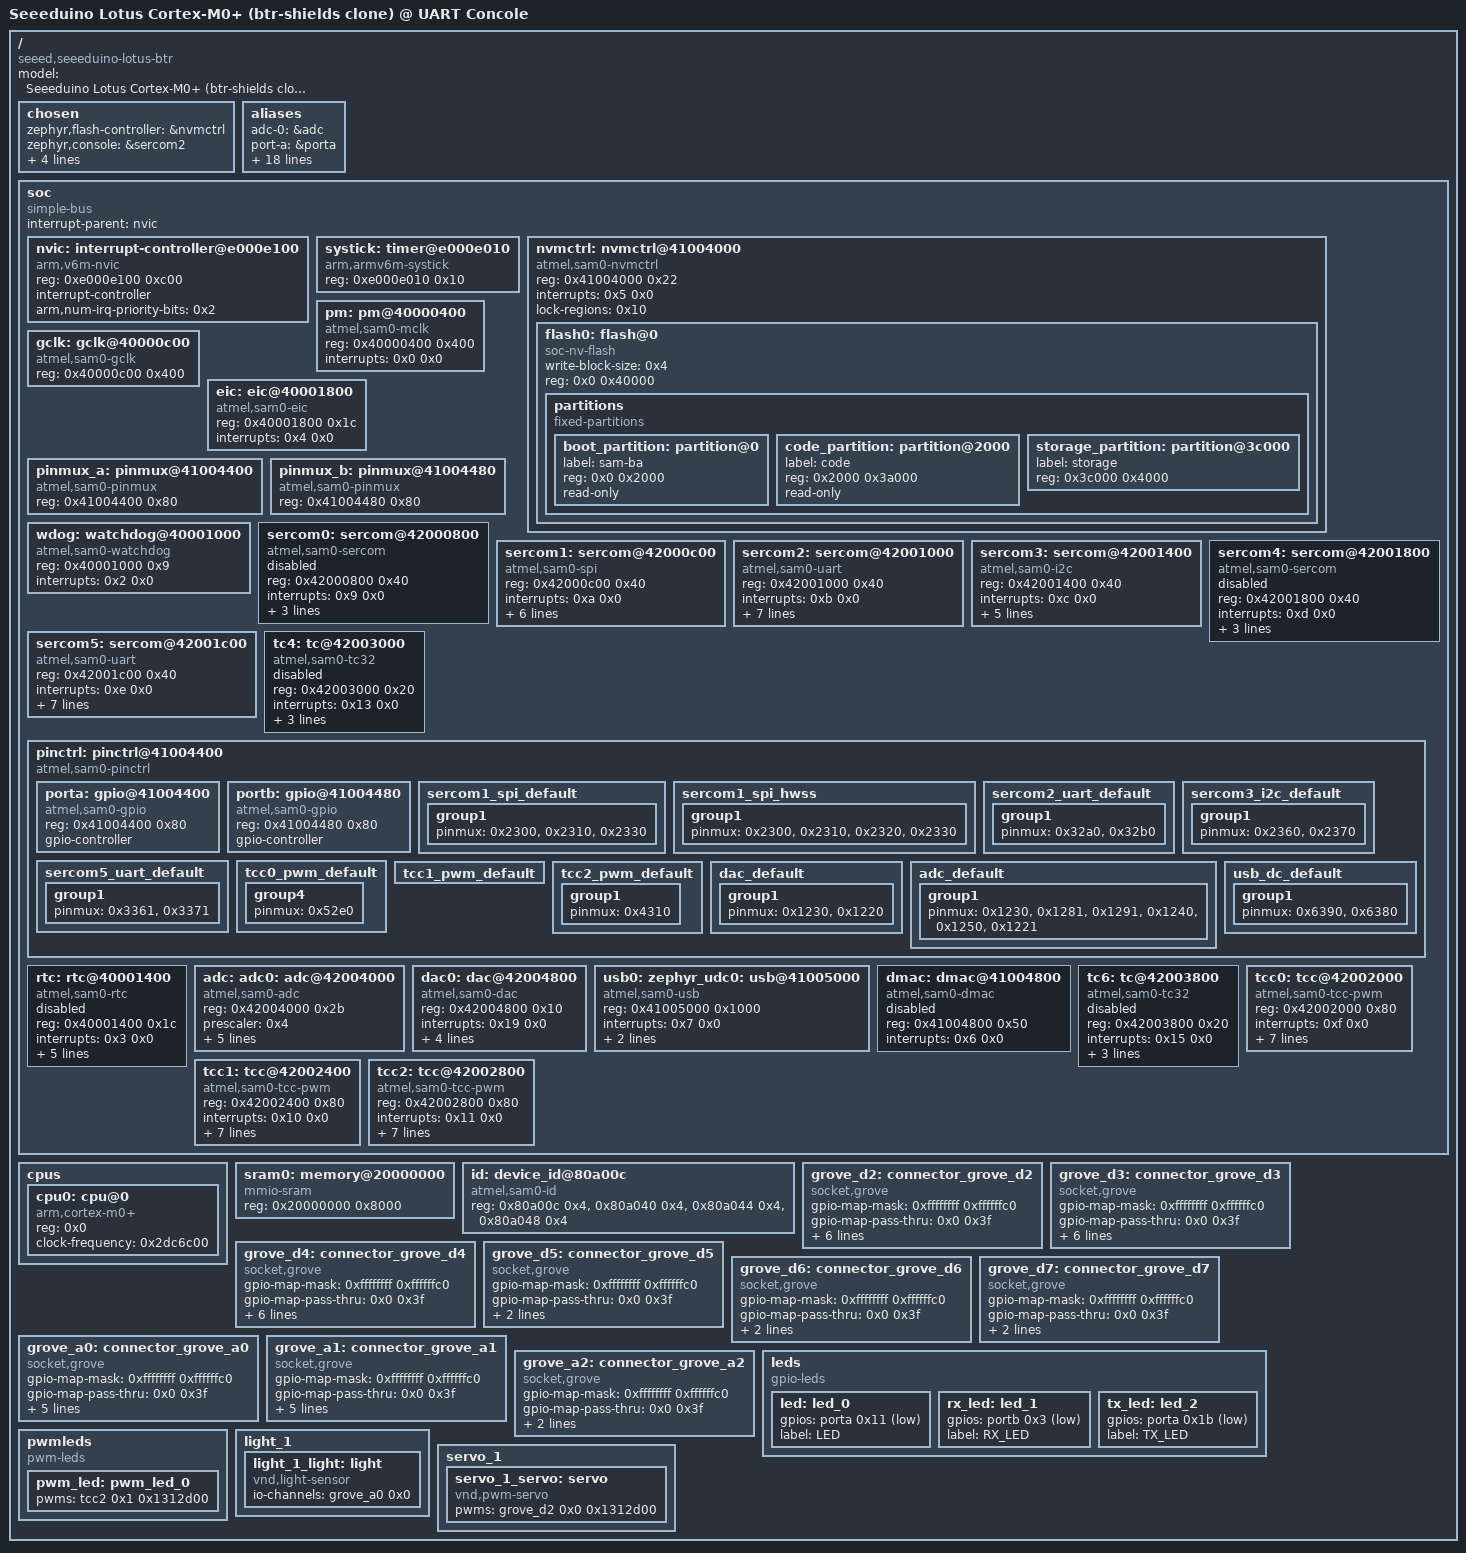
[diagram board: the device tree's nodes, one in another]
/dts-v1/;

/* node '/' defined in zephyr-rigs/dts/common/skeleton.dtsi:9 */
/ {
	#address-cells = < 0x1 >;                                                /* in zephyr-rigs/dts/common/skeleton.dtsi:10 */
	#size-cells = < 0x1 >;                                                   /* in zephyr-rigs/dts/common/skeleton.dtsi:11 */
	model = "Seeeduino Lotus Cortex-M0+ (btr-shields clone) @ UART Concole"; /* in btr-shields/boards/seeed/seeeduino_lotus_btr/seeeduino_lotus_btr.dts:28 */
	compatible = "seeed,seeeduino-lotus-btr",
	             "seeed,seeeduino-lotus-uartcons";                           /* in btr-shields/boards/seeed/seeeduino_lotus_btr/seeeduino_lotus_btr.dts:29 */

	/* node '/chosen' defined in zephyr-rigs/dts/common/skeleton.dtsi:13 */
	chosen {
		zephyr,flash-controller = &nvmctrl;      /* in zephyr-rigs/dts/arm/atmel/samd2x.dtsi:37 */
		zephyr,console = &sercom2;               /* in btr-shields/boards/seeed/seeeduino_lotus_btr/seeeduino_lotus_btr.dts:32 */
		zephyr,shell-uart = &sercom2;            /* in btr-shields/boards/seeed/seeeduino_lotus_btr/seeeduino_lotus_btr.dts:33 */
		zephyr,sram = &sram0;                    /* in btr-shields/boards/seeed/seeeduino_lotus_btr/seeeduino_lotus_btr.dts:34 */
		zephyr,flash = &flash0;                  /* in btr-shields/boards/seeed/seeeduino_lotus_btr/seeeduino_lotus_btr.dts:35 */
		zephyr,code-partition = &code_partition; /* in btr-shields/boards/seeed/seeeduino_lotus_btr/seeeduino_lotus_btr.dts:36 */
	};

	/* node '/aliases' defined in zephyr-rigs/dts/common/skeleton.dtsi:15 */
	aliases {
		adc-0 = &adc;        /* in zephyr-rigs/dts/arm/atmel/samd2x.dtsi:17 */
		port-a = &porta;     /* in zephyr-rigs/dts/arm/atmel/samd2x.dtsi:19 */
		port-b = &portb;     /* in zephyr-rigs/dts/arm/atmel/samd2x.dtsi:20 */
		rtc = &rtc;          /* in zephyr-rigs/dts/arm/atmel/samd2x.dtsi:22 */
		sercom-0 = &sercom0; /* in zephyr-rigs/dts/arm/atmel/samd2x.dtsi:24 */
		sercom-1 = &sercom1; /* in zephyr-rigs/dts/arm/atmel/samd2x.dtsi:25 */
		sercom-2 = &sercom2; /* in zephyr-rigs/dts/arm/atmel/samd2x.dtsi:26 */
		sercom-3 = &sercom3; /* in zephyr-rigs/dts/arm/atmel/samd2x.dtsi:27 */
		sercom-4 = &sercom4; /* in zephyr-rigs/dts/arm/atmel/samd2x.dtsi:28 */
		sercom-5 = &sercom5; /* in zephyr-rigs/dts/arm/atmel/samd2x.dtsi:29 */
		tc-4 = &tc4;         /* in zephyr-rigs/dts/arm/atmel/samd2x.dtsi:31 */
		watchdog0 = &wdog;   /* in zephyr-rigs/dts/arm/atmel/samd2x.dtsi:33 */
		tc-6 = &tc6;         /* in zephyr-rigs/dts/arm/atmel/samd21.dtsi:12 */
		tcc-0 = &tcc0;       /* in zephyr-rigs/dts/arm/atmel/samd21.dtsi:14 */
		tcc-1 = &tcc1;       /* in zephyr-rigs/dts/arm/atmel/samd21.dtsi:15 */
		tcc-2 = &tcc2;       /* in zephyr-rigs/dts/arm/atmel/samd21.dtsi:16 */
		led0 = &led;         /* in btr-shields/boards/seeed/seeeduino_lotus_btr/seeeduino_lotus_btr.dts:64 */
		led1 = &rx_led;      /* in btr-shields/boards/seeed/seeeduino_lotus_btr/seeeduino_lotus_btr.dts:65 */
		led2 = &tx_led;      /* in btr-shields/boards/seeed/seeeduino_lotus_btr/seeeduino_lotus_btr.dts:66 */
		pwm-led0 = &pwm_led; /* in btr-shields/boards/seeed/seeeduino_lotus_btr/seeeduino_lotus_btr.dts:67 */
	};

	/* node '/soc' defined in zephyr-rigs/dts/arm/armv6-m.dtsi:6 */
	soc {
		#address-cells = < 0x1 >;     /* in zephyr-rigs/dts/arm/armv6-m.dtsi:7 */
		#size-cells = < 0x1 >;        /* in zephyr-rigs/dts/arm/armv6-m.dtsi:8 */
		compatible = "simple-bus";    /* in zephyr-rigs/dts/arm/armv6-m.dtsi:9 */
		interrupt-parent = < &nvic >; /* in zephyr-rigs/dts/arm/armv6-m.dtsi:10 */
		ranges;                       /* in zephyr-rigs/dts/arm/armv6-m.dtsi:11 */

		/* node '/soc/interrupt-controller@e000e100' defined in zephyr-rigs/dts/arm/armv6-m.dtsi:13 */
		nvic: interrupt-controller@e000e100 {
			#address-cells = < 0x1 >;            /* in zephyr-rigs/dts/arm/armv6-m.dtsi:14 */
			compatible = "arm,v6m-nvic";         /* in zephyr-rigs/dts/arm/armv6-m.dtsi:15 */
			reg = < 0xe000e100 0xc00 >;          /* in zephyr-rigs/dts/arm/armv6-m.dtsi:16 */
			interrupt-controller;                /* in zephyr-rigs/dts/arm/armv6-m.dtsi:17 */
			#interrupt-cells = < 0x2 >;          /* in zephyr-rigs/dts/arm/armv6-m.dtsi:18 */
			arm,num-irq-priority-bits = < 0x2 >; /* in zephyr-rigs/dts/arm/atmel/samd2x.dtsi:227 */
			phandle = < 0x1 >;                   /* in zephyr-rigs/dts/arm/armv6-m.dtsi:10 */
		};

		/* node '/soc/timer@e000e010' defined in zephyr-rigs/dts/arm/armv6-m.dtsi:21 */
		systick: timer@e000e010 {
			compatible = "arm,armv6m-systick"; /* in zephyr-rigs/dts/arm/armv6-m.dtsi:22 */
			reg = < 0xe000e010 0x10 >;         /* in zephyr-rigs/dts/arm/armv6-m.dtsi:23 */
		};

		/* node '/soc/nvmctrl@41004000' defined in zephyr-rigs/dts/arm/atmel/samd2x.dtsi:65 */
		nvmctrl: nvmctrl@41004000 {
			compatible = "atmel,sam0-nvmctrl"; /* in zephyr-rigs/dts/arm/atmel/samd2x.dtsi:66 */
			reg = < 0x41004000 0x22 >;         /* in zephyr-rigs/dts/arm/atmel/samd2x.dtsi:67 */
			interrupts = < 0x5 0x0 >;          /* in zephyr-rigs/dts/arm/atmel/samd2x.dtsi:68 */
			#address-cells = < 0x1 >;          /* in zephyr-rigs/dts/arm/atmel/samd2x.dtsi:70 */
			#size-cells = < 0x1 >;             /* in zephyr-rigs/dts/arm/atmel/samd2x.dtsi:71 */
			ranges;                            /* in zephyr-rigs/dts/arm/atmel/samd2x.dtsi:72 */
			lock-regions = < 0x10 >;           /* in zephyr-rigs/dts/arm/atmel/samd2x.dtsi:74 */

			/* node '/soc/nvmctrl@41004000/flash@0' defined in zephyr-rigs/dts/arm/atmel/samd2x.dtsi:76 */
			flash0: flash@0 {
				compatible = "soc-nv-flash";  /* in zephyr-rigs/dts/arm/atmel/samd2x.dtsi:77 */
				write-block-size = < 0x4 >;   /* in zephyr-rigs/dts/arm/atmel/samd2x.dtsi:79 */
				#address-cells = < 0x1 >;     /* in zephyr-rigs/dts/arm/atmel/samd2x.dtsi:80 */
				#size-cells = < 0x1 >;        /* in zephyr-rigs/dts/arm/atmel/samd2x.dtsi:81 */
				reg = < 0x0 0x40000 >;        /* in zephyr-rigs/dts/arm/atmel/samx2xx18.dtsi:14 */
				ranges = < 0x0 0x0 0x40000 >; /* in zephyr-rigs/dts/arm/atmel/samx2xx18.dtsi:15 */

				/* node '/soc/nvmctrl@41004000/flash@0/partitions' defined in btr-shields/boards/seeed/seeeduino_lotus_btr/seeeduino_lotus_btr.dts:176 */
				partitions {
					compatible = "fixed-partitions"; /* in btr-shields/boards/seeed/seeeduino_lotus_btr/seeeduino_lotus_btr.dts:177 */
					#address-cells = < 0x1 >;        /* in btr-shields/boards/seeed/seeeduino_lotus_btr/seeeduino_lotus_btr.dts:178 */
					#size-cells = < 0x1 >;           /* in btr-shields/boards/seeed/seeeduino_lotus_btr/seeeduino_lotus_btr.dts:179 */

					/* node '/soc/nvmctrl@41004000/flash@0/partitions/partition@0' defined in btr-shields/boards/seeed/seeeduino_lotus_btr/seeeduino_lotus_btr.dts:181 */
					boot_partition: partition@0 {
						label = "sam-ba";     /* in btr-shields/boards/seeed/seeeduino_lotus_btr/seeeduino_lotus_btr.dts:182 */
						reg = < 0x0 0x2000 >; /* in btr-shields/boards/seeed/seeeduino_lotus_btr/seeeduino_lotus_btr.dts:183 */
						read-only;            /* in btr-shields/boards/seeed/seeeduino_lotus_btr/seeeduino_lotus_btr.dts:184 */
					};

					/* node '/soc/nvmctrl@41004000/flash@0/partitions/partition@2000' defined in btr-shields/boards/seeed/seeeduino_lotus_btr/seeeduino_lotus_btr.dts:187 */
					code_partition: partition@2000 {
						label = "code";           /* in btr-shields/boards/seeed/seeeduino_lotus_btr/seeeduino_lotus_btr.dts:188 */
						reg = < 0x2000 0x3a000 >; /* in btr-shields/boards/seeed/seeeduino_lotus_btr/seeeduino_lotus_btr.dts:189 */
						read-only;                /* in btr-shields/boards/seeed/seeeduino_lotus_btr/seeeduino_lotus_btr.dts:190 */
					};

					/* node '/soc/nvmctrl@41004000/flash@0/partitions/partition@3c000' defined in btr-shields/boards/seeed/seeeduino_lotus_btr/seeeduino_lotus_btr.dts:197 */
					storage_partition: partition@3c000 {
						label = "storage";        /* in btr-shields/boards/seeed/seeeduino_lotus_btr/seeeduino_lotus_btr.dts:198 */
						reg = < 0x3c000 0x4000 >; /* in btr-shields/boards/seeed/seeeduino_lotus_btr/seeeduino_lotus_btr.dts:199 */
					};
				};
			};
		};

		/* node '/soc/pm@40000400' defined in zephyr-rigs/dts/arm/atmel/samd2x.dtsi:86 */
		pm: pm@40000400 {
			compatible = "atmel,sam0-mclk"; /* in zephyr-rigs/dts/arm/atmel/samd2x.dtsi:87 */
			reg = < 0x40000400 0x400 >;     /* in zephyr-rigs/dts/arm/atmel/samd2x.dtsi:88 */
			interrupts = < 0x0 0x0 >;       /* in zephyr-rigs/dts/arm/atmel/samd2x.dtsi:89 */
			#clock-cells = < 0x2 >;         /* in zephyr-rigs/dts/arm/atmel/samd2x.dtsi:91 */
			phandle = < 0x3 >;              /* in zephyr-rigs/dts/arm/atmel/samd21.dtsi:110 */
		};

		/* node '/soc/gclk@40000c00' defined in zephyr-rigs/dts/arm/atmel/samd2x.dtsi:94 */
		gclk: gclk@40000c00 {
			compatible = "atmel,sam0-gclk";        /* in zephyr-rigs/dts/arm/atmel/samd2x.dtsi:95 */
			reg = < 0x40000c00 0x400 >;            /* in zephyr-rigs/dts/arm/atmel/samd2x.dtsi:96 */
			#clock-cells = < 0x1 >;                /* in zephyr-rigs/dts/arm/atmel/samd2x.dtsi:98 */
			#atmel,assigned-clock-cells = < 0x1 >; /* in zephyr-rigs/dts/arm/atmel/samd2x.dtsi:99 */
			phandle = < 0x2 >;                     /* in zephyr-rigs/dts/arm/atmel/samd21.dtsi:110 */
		};

		/* node '/soc/eic@40001800' defined in zephyr-rigs/dts/arm/atmel/samd2x.dtsi:102 */
		eic: eic@40001800 {
			compatible = "atmel,sam0-eic"; /* in zephyr-rigs/dts/arm/atmel/samd2x.dtsi:103 */
			reg = < 0x40001800 0x1c >;     /* in zephyr-rigs/dts/arm/atmel/samd2x.dtsi:104 */
			interrupts = < 0x4 0x0 >;      /* in zephyr-rigs/dts/arm/atmel/samd2x.dtsi:105 */
		};

		/* node '/soc/pinmux@41004400' defined in zephyr-rigs/dts/arm/atmel/samd2x.dtsi:108 */
		pinmux_a: pinmux@41004400 {
			compatible = "atmel,sam0-pinmux"; /* in zephyr-rigs/dts/arm/atmel/samd2x.dtsi:109 */
			reg = < 0x41004400 0x80 >;        /* in zephyr-rigs/dts/arm/atmel/samd2x.dtsi:110 */
		};

		/* node '/soc/pinmux@41004480' defined in zephyr-rigs/dts/arm/atmel/samd2x.dtsi:113 */
		pinmux_b: pinmux@41004480 {
			compatible = "atmel,sam0-pinmux"; /* in zephyr-rigs/dts/arm/atmel/samd2x.dtsi:114 */
			reg = < 0x41004480 0x80 >;        /* in zephyr-rigs/dts/arm/atmel/samd2x.dtsi:115 */
		};

		/* node '/soc/watchdog@40001000' defined in zephyr-rigs/dts/arm/atmel/samd2x.dtsi:118 */
		wdog: watchdog@40001000 {
			compatible = "atmel,sam0-watchdog"; /* in zephyr-rigs/dts/arm/atmel/samd2x.dtsi:119 */
			reg = < 0x40001000 0x9 >;           /* in zephyr-rigs/dts/arm/atmel/samd2x.dtsi:120 */
			interrupts = < 0x2 0x0 >;           /* in zephyr-rigs/dts/arm/atmel/samd2x.dtsi:121 */
		};

		/* node '/soc/sercom@42000800' defined in zephyr-rigs/dts/arm/atmel/samd2x.dtsi:124 */
		sercom0: sercom@42000800 {
			compatible = "atmel,sam0-sercom";      /* in zephyr-rigs/dts/arm/atmel/samd2x.dtsi:125 */
			reg = < 0x42000800 0x40 >;             /* in zephyr-rigs/dts/arm/atmel/samd2x.dtsi:126 */
			status = "disabled";                   /* in zephyr-rigs/dts/arm/atmel/samd2x.dtsi:127 */
			interrupts = < 0x9 0x0 >;              /* in zephyr-rigs/dts/arm/atmel/samd21.dtsi:109 */
			clocks = < &gclk 0x14 >,
			         < &pm 0x20 0x2 >;             /* in zephyr-rigs/dts/arm/atmel/samd21.dtsi:110 */
			clock-names = "GCLK",
			              "PM";                    /* in zephyr-rigs/dts/arm/atmel/samd21.dtsi:111 */
			atmel,assigned-clocks = < &gclk 0x0 >; /* in zephyr-rigs/dts/arm/atmel/samd21.dtsi:112 */
			atmel,assigned-clock-names = "GCLK";   /* in zephyr-rigs/dts/arm/atmel/samd21.dtsi:113 */
		};

		/* node '/soc/sercom@42000c00' defined in zephyr-rigs/dts/arm/atmel/samd2x.dtsi:130 */
		sercom1: sercom@42000c00 {
			reg = < 0x42000c00 0x40 >;             /* in zephyr-rigs/dts/arm/atmel/samd2x.dtsi:132 */
			interrupts = < 0xa 0x0 >;              /* in zephyr-rigs/dts/arm/atmel/samd21.dtsi:117 */
			clocks = < &gclk 0x15 >,
			         < &pm 0x20 0x3 >;             /* in zephyr-rigs/dts/arm/atmel/samd21.dtsi:118 */
			clock-names = "GCLK",
			              "PM";                    /* in zephyr-rigs/dts/arm/atmel/samd21.dtsi:119 */
			atmel,assigned-clocks = < &gclk 0x0 >; /* in zephyr-rigs/dts/arm/atmel/samd21.dtsi:120 */
			atmel,assigned-clock-names = "GCLK";   /* in zephyr-rigs/dts/arm/atmel/samd21.dtsi:121 */
			status = "okay";                       /* in btr-shields/boards/seeed/seeeduino_lotus_btr/seeeduino_lotus_btr.dts:76 */
			compatible = "atmel,sam0-spi";         /* in btr-shields/boards/seeed/seeeduino_lotus_btr/seeeduino_lotus_btr.dts:77 */
			dipo = < 0x3 >;                        /* in btr-shields/boards/seeed/seeeduino_lotus_btr/seeeduino_lotus_btr.dts:78 */
			dopo = < 0x0 >;                        /* in btr-shields/boards/seeed/seeeduino_lotus_btr/seeeduino_lotus_btr.dts:79 */
			#address-cells = < 0x1 >;              /* in btr-shields/boards/seeed/seeeduino_lotus_btr/seeeduino_lotus_btr.dts:80 */
			#size-cells = < 0x0 >;                 /* in btr-shields/boards/seeed/seeeduino_lotus_btr/seeeduino_lotus_btr.dts:81 */
			pinctrl-0 = < &sercom1_spi_default >;  /* in btr-shields/boards/seeed/seeeduino_lotus_btr/seeeduino_lotus_btr.dts:86 */
			pinctrl-names = "default";             /* in btr-shields/boards/seeed/seeeduino_lotus_btr/seeeduino_lotus_btr.dts:87 */
		};

		/* node '/soc/sercom@42001000' defined in zephyr-rigs/dts/arm/atmel/samd2x.dtsi:136 */
		sercom2: sercom@42001000 {
			reg = < 0x42001000 0x40 >;             /* in zephyr-rigs/dts/arm/atmel/samd2x.dtsi:138 */
			interrupts = < 0xb 0x0 >;              /* in zephyr-rigs/dts/arm/atmel/samd21.dtsi:125 */
			clocks = < &gclk 0x16 >,
			         < &pm 0x20 0x4 >;             /* in zephyr-rigs/dts/arm/atmel/samd21.dtsi:126 */
			clock-names = "GCLK",
			              "PM";                    /* in zephyr-rigs/dts/arm/atmel/samd21.dtsi:127 */
			atmel,assigned-clocks = < &gclk 0x0 >; /* in zephyr-rigs/dts/arm/atmel/samd21.dtsi:128 */
			atmel,assigned-clock-names = "GCLK";   /* in zephyr-rigs/dts/arm/atmel/samd21.dtsi:129 */
			status = "okay";                       /* in btr-shields/boards/seeed/seeeduino_lotus_btr/seeeduino_lotus_btr.dts:91 */
			compatible = "atmel,sam0-uart";        /* in btr-shields/boards/seeed/seeeduino_lotus_btr/seeeduino_lotus_btr.dts:92 */
			current-speed = < 0x1c200 >;           /* in btr-shields/boards/seeed/seeeduino_lotus_btr/seeeduino_lotus_btr.dts:93 */
			rxpo = < 0x3 >;                        /* in btr-shields/boards/seeed/seeeduino_lotus_btr/seeeduino_lotus_btr.dts:94 */
			txpo = < 0x1 >;                        /* in btr-shields/boards/seeed/seeeduino_lotus_btr/seeeduino_lotus_btr.dts:95 */
			pinctrl-0 = < &sercom2_uart_default >; /* in btr-shields/boards/seeed/seeeduino_lotus_btr/seeeduino_lotus_btr.dts:97 */
			pinctrl-names = "default";             /* in btr-shields/boards/seeed/seeeduino_lotus_btr/seeeduino_lotus_btr.dts:98 */
		};

		/* node '/soc/sercom@42001400' defined in zephyr-rigs/dts/arm/atmel/samd2x.dtsi:142 */
		sercom3: sercom@42001400 {
			reg = < 0x42001400 0x40 >;             /* in zephyr-rigs/dts/arm/atmel/samd2x.dtsi:144 */
			interrupts = < 0xc 0x0 >;              /* in zephyr-rigs/dts/arm/atmel/samd21.dtsi:133 */
			clocks = < &gclk 0x17 >,
			         < &pm 0x20 0x5 >;             /* in zephyr-rigs/dts/arm/atmel/samd21.dtsi:134 */
			clock-names = "GCLK",
			              "PM";                    /* in zephyr-rigs/dts/arm/atmel/samd21.dtsi:135 */
			atmel,assigned-clocks = < &gclk 0x0 >; /* in zephyr-rigs/dts/arm/atmel/samd21.dtsi:136 */
			atmel,assigned-clock-names = "GCLK";   /* in zephyr-rigs/dts/arm/atmel/samd21.dtsi:137 */
			status = "okay";                       /* in btr-shields/boards/seeed/seeeduino_lotus_btr/seeeduino_lotus_btr.dts:102 */
			compatible = "atmel,sam0-i2c";         /* in btr-shields/boards/seeed/seeeduino_lotus_btr/seeeduino_lotus_btr.dts:103 */
			clock-frequency = < 0x61a80 >;         /* in btr-shields/boards/seeed/seeeduino_lotus_btr/seeeduino_lotus_btr.dts:104 */
			#address-cells = < 0x1 >;              /* in btr-shields/boards/seeed/seeeduino_lotus_btr/seeeduino_lotus_btr.dts:105 */
			#size-cells = < 0x0 >;                 /* in btr-shields/boards/seeed/seeeduino_lotus_btr/seeeduino_lotus_btr.dts:106 */
			pinctrl-0 = < &sercom3_i2c_default >;  /* in btr-shields/boards/seeed/seeeduino_lotus_btr/seeeduino_lotus_btr.dts:108 */
			pinctrl-names = "default";             /* in btr-shields/boards/seeed/seeeduino_lotus_btr/seeeduino_lotus_btr.dts:109 */
		};

		/* node '/soc/sercom@42001800' defined in zephyr-rigs/dts/arm/atmel/samd2x.dtsi:148 */
		sercom4: sercom@42001800 {
			compatible = "atmel,sam0-sercom";      /* in zephyr-rigs/dts/arm/atmel/samd2x.dtsi:149 */
			reg = < 0x42001800 0x40 >;             /* in zephyr-rigs/dts/arm/atmel/samd2x.dtsi:150 */
			status = "disabled";                   /* in zephyr-rigs/dts/arm/atmel/samd2x.dtsi:151 */
			interrupts = < 0xd 0x0 >;              /* in zephyr-rigs/dts/arm/atmel/samd21.dtsi:141 */
			clocks = < &gclk 0x18 >,
			         < &pm 0x20 0x6 >;             /* in zephyr-rigs/dts/arm/atmel/samd21.dtsi:142 */
			clock-names = "GCLK",
			              "PM";                    /* in zephyr-rigs/dts/arm/atmel/samd21.dtsi:143 */
			atmel,assigned-clocks = < &gclk 0x0 >; /* in zephyr-rigs/dts/arm/atmel/samd21.dtsi:144 */
			atmel,assigned-clock-names = "GCLK";   /* in zephyr-rigs/dts/arm/atmel/samd21.dtsi:145 */
		};

		/* node '/soc/sercom@42001c00' defined in zephyr-rigs/dts/arm/atmel/samd2x.dtsi:154 */
		sercom5: sercom@42001c00 {
			reg = < 0x42001c00 0x40 >;             /* in zephyr-rigs/dts/arm/atmel/samd2x.dtsi:156 */
			interrupts = < 0xe 0x0 >;              /* in zephyr-rigs/dts/arm/atmel/samd21.dtsi:149 */
			clocks = < &gclk 0x19 >,
			         < &pm 0x20 0x7 >;             /* in zephyr-rigs/dts/arm/atmel/samd21.dtsi:150 */
			clock-names = "GCLK",
			              "PM";                    /* in zephyr-rigs/dts/arm/atmel/samd21.dtsi:151 */
			atmel,assigned-clocks = < &gclk 0x0 >; /* in zephyr-rigs/dts/arm/atmel/samd21.dtsi:152 */
			atmel,assigned-clock-names = "GCLK";   /* in zephyr-rigs/dts/arm/atmel/samd21.dtsi:153 */
			status = "okay";                       /* in btr-shields/boards/seeed/seeeduino_lotus_btr/seeeduino_lotus_btr.dts:113 */
			compatible = "atmel,sam0-uart";        /* in btr-shields/boards/seeed/seeeduino_lotus_btr/seeeduino_lotus_btr.dts:114 */
			current-speed = < 0x1c200 >;           /* in btr-shields/boards/seeed/seeeduino_lotus_btr/seeeduino_lotus_btr.dts:115 */
			rxpo = < 0x3 >;                        /* in btr-shields/boards/seeed/seeeduino_lotus_btr/seeeduino_lotus_btr.dts:116 */
			txpo = < 0x1 >;                        /* in btr-shields/boards/seeed/seeeduino_lotus_btr/seeeduino_lotus_btr.dts:117 */
			pinctrl-0 = < &sercom5_uart_default >; /* in btr-shields/boards/seeed/seeeduino_lotus_btr/seeeduino_lotus_btr.dts:119 */
			pinctrl-names = "default";             /* in btr-shields/boards/seeed/seeeduino_lotus_btr/seeeduino_lotus_btr.dts:120 */
		};

		/* node '/soc/tc@42003000' defined in zephyr-rigs/dts/arm/atmel/samd2x.dtsi:160 */
		tc4: tc@42003000 {
			compatible = "atmel,sam0-tc32";        /* in zephyr-rigs/dts/arm/atmel/samd2x.dtsi:161 */
			reg = < 0x42003000 0x20 >;             /* in zephyr-rigs/dts/arm/atmel/samd2x.dtsi:162 */
			status = "disabled";                   /* in zephyr-rigs/dts/arm/atmel/samd2x.dtsi:163 */
			interrupts = < 0x13 0x0 >;             /* in zephyr-rigs/dts/arm/atmel/samd21.dtsi:157 */
			clocks = < &gclk 0x1c >,
			         < &pm 0x20 0xc >;             /* in zephyr-rigs/dts/arm/atmel/samd21.dtsi:158 */
			clock-names = "GCLK",
			              "PM";                    /* in zephyr-rigs/dts/arm/atmel/samd21.dtsi:159 */
			atmel,assigned-clocks = < &gclk 0x0 >; /* in zephyr-rigs/dts/arm/atmel/samd21.dtsi:160 */
			atmel,assigned-clock-names = "GCLK";   /* in zephyr-rigs/dts/arm/atmel/samd21.dtsi:161 */
		};

		/* node '/soc/pinctrl@41004400' defined in zephyr-rigs/dts/arm/atmel/samd2x.dtsi:166 */
		pinctrl: pinctrl@41004400 {
			compatible = "atmel,sam0-pinctrl";        /* in zephyr-rigs/dts/arm/atmel/samd2x.dtsi:167 */
			ranges = < 0x41004400 0x41004400 0x100 >; /* in zephyr-rigs/dts/arm/atmel/samd2x.dtsi:168 */
			#address-cells = < 0x1 >;                 /* in zephyr-rigs/dts/arm/atmel/samd2x.dtsi:170 */
			#size-cells = < 0x1 >;                    /* in zephyr-rigs/dts/arm/atmel/samd2x.dtsi:171 */

			/* node '/soc/pinctrl@41004400/gpio@41004400' defined in zephyr-rigs/dts/arm/atmel/samd2x.dtsi:173 */
			porta: gpio@41004400 {
				compatible = "atmel,sam0-gpio"; /* in zephyr-rigs/dts/arm/atmel/samd2x.dtsi:174 */
				reg = < 0x41004400 0x80 >;      /* in zephyr-rigs/dts/arm/atmel/samd2x.dtsi:175 */
				#atmel,pin-cells = < 0x2 >;     /* in zephyr-rigs/dts/arm/atmel/samd2x.dtsi:177 */
				#gpio-cells = < 0x2 >;          /* in zephyr-rigs/dts/arm/atmel/samd2x.dtsi:178 */
				gpio-controller;                /* in zephyr-rigs/dts/arm/atmel/samd2x.dtsi:180 */
				phandle = < 0xe >;              /* in btr-shields/boards/seeed/seeeduino_lotus_btr/grove_sockets_btr.dtsi:67 */
			};

			/* node '/soc/pinctrl@41004400/gpio@41004480' defined in zephyr-rigs/dts/arm/atmel/samd2x.dtsi:183 */
			portb: gpio@41004480 {
				compatible = "atmel,sam0-gpio"; /* in zephyr-rigs/dts/arm/atmel/samd2x.dtsi:184 */
				reg = < 0x41004480 0x80 >;      /* in zephyr-rigs/dts/arm/atmel/samd2x.dtsi:185 */
				#atmel,pin-cells = < 0x2 >;     /* in zephyr-rigs/dts/arm/atmel/samd2x.dtsi:187 */
				#gpio-cells = < 0x2 >;          /* in zephyr-rigs/dts/arm/atmel/samd2x.dtsi:188 */
				gpio-controller;                /* in zephyr-rigs/dts/arm/atmel/samd2x.dtsi:190 */
				phandle = < 0x10 >;             /* in btr-shields/boards/seeed/seeeduino_lotus_btr/grove_sockets_btr.dtsi:132 */
			};

			/* node '/soc/pinctrl@41004400/sercom1_spi_default' defined in btr-shields/boards/seeed/seeeduino_lotus_btr/seeeduino_lotus_btr-pinctrl.dtsi:9 */
			sercom1_spi_default: sercom1_spi_default {
				phandle = < 0x4 >; /* in btr-shields/boards/seeed/seeeduino_lotus_btr/seeeduino_lotus_btr.dts:86 */

				/* node '/soc/pinctrl@41004400/sercom1_spi_default/group1' defined in btr-shields/boards/seeed/seeeduino_lotus_btr/seeeduino_lotus_btr-pinctrl.dtsi:10 */
				group1 {
					pinmux = < 0x2300 >,
					         < 0x2310 >,
					         < 0x2330 >; /* in btr-shields/boards/seeed/seeeduino_lotus_btr/seeeduino_lotus_btr-pinctrl.dtsi:11 */
				};
			};

			/* node '/soc/pinctrl@41004400/sercom1_spi_hwss' defined in btr-shields/boards/seeed/seeeduino_lotus_btr/seeeduino_lotus_btr-pinctrl.dtsi:17 */
			sercom1_spi_hwss: sercom1_spi_hwss {

				/* node '/soc/pinctrl@41004400/sercom1_spi_hwss/group1' defined in btr-shields/boards/seeed/seeeduino_lotus_btr/seeeduino_lotus_btr-pinctrl.dtsi:18 */
				group1 {
					pinmux = < 0x2300 >,
					         < 0x2310 >,
					         < 0x2320 >,
					         < 0x2330 >; /* in btr-shields/boards/seeed/seeeduino_lotus_btr/seeeduino_lotus_btr-pinctrl.dtsi:19 */
				};
			};

			/* node '/soc/pinctrl@41004400/sercom2_uart_default' defined in btr-shields/boards/seeed/seeeduino_lotus_btr/seeeduino_lotus_btr-pinctrl.dtsi:26 */
			sercom2_uart_default: sercom2_uart_default {
				phandle = < 0x5 >; /* in btr-shields/boards/seeed/seeeduino_lotus_btr/seeeduino_lotus_btr.dts:97 */

				/* node '/soc/pinctrl@41004400/sercom2_uart_default/group1' defined in btr-shields/boards/seeed/seeeduino_lotus_btr/seeeduino_lotus_btr-pinctrl.dtsi:27 */
				group1 {
					pinmux = < 0x32a0 >,
					         < 0x32b0 >; /* in btr-shields/boards/seeed/seeeduino_lotus_btr/seeeduino_lotus_btr-pinctrl.dtsi:28 */
				};
			};

			/* node '/soc/pinctrl@41004400/sercom3_i2c_default' defined in btr-shields/boards/seeed/seeeduino_lotus_btr/seeeduino_lotus_btr-pinctrl.dtsi:33 */
			sercom3_i2c_default: sercom3_i2c_default {
				phandle = < 0x6 >; /* in btr-shields/boards/seeed/seeeduino_lotus_btr/seeeduino_lotus_btr.dts:108 */

				/* node '/soc/pinctrl@41004400/sercom3_i2c_default/group1' defined in btr-shields/boards/seeed/seeeduino_lotus_btr/seeeduino_lotus_btr-pinctrl.dtsi:34 */
				group1 {
					pinmux = < 0x2360 >,
					         < 0x2370 >; /* in btr-shields/boards/seeed/seeeduino_lotus_btr/seeeduino_lotus_btr-pinctrl.dtsi:35 */
				};
			};

			/* node '/soc/pinctrl@41004400/sercom5_uart_default' defined in btr-shields/boards/seeed/seeeduino_lotus_btr/seeeduino_lotus_btr-pinctrl.dtsi:40 */
			sercom5_uart_default: sercom5_uart_default {
				phandle = < 0x7 >; /* in btr-shields/boards/seeed/seeeduino_lotus_btr/seeeduino_lotus_btr.dts:119 */

				/* node '/soc/pinctrl@41004400/sercom5_uart_default/group1' defined in btr-shields/boards/seeed/seeeduino_lotus_btr/seeeduino_lotus_btr-pinctrl.dtsi:41 */
				group1 {
					pinmux = < 0x3361 >,
					         < 0x3371 >; /* in btr-shields/boards/seeed/seeeduino_lotus_btr/seeeduino_lotus_btr-pinctrl.dtsi:42 */
				};
			};

			/* node '/soc/pinctrl@41004400/tcc0_pwm_default' defined in btr-shields/boards/seeed/seeeduino_lotus_btr/seeeduino_lotus_btr-pinctrl.dtsi:47 */
			tcc0_pwm_default: tcc0_pwm_default {
				phandle = < 0xb >; /* in btr-shields/boards/seeed/seeeduino_lotus_btr/seeeduino_lotus_btr.dts:129 */

				/* node '/soc/pinctrl@41004400/tcc0_pwm_default/group4' defined in btr-shields/boards/rigs/lotus-pwm/rig.overlay:23 */
				group4 {
					pinmux = < 0x52e0 >; /* in btr-shields/boards/rigs/lotus-pwm/rig.overlay:24 */
				};
			};

			/* node '/soc/pinctrl@41004400/tcc1_pwm_default' defined in btr-shields/boards/seeed/seeeduino_lotus_btr/seeeduino_lotus_btr-pinctrl.dtsi:49 */
			tcc1_pwm_default: tcc1_pwm_default {
				phandle = < 0xc >; /* in btr-shields/boards/seeed/seeeduino_lotus_btr/seeeduino_lotus_btr.dts:139 */
			};

			/* node '/soc/pinctrl@41004400/tcc2_pwm_default' defined in btr-shields/boards/seeed/seeeduino_lotus_btr/seeeduino_lotus_btr-pinctrl.dtsi:51 */
			tcc2_pwm_default: tcc2_pwm_default {
				phandle = < 0xd >; /* in btr-shields/boards/seeed/seeeduino_lotus_btr/seeeduino_lotus_btr.dts:150 */

				/* node '/soc/pinctrl@41004400/tcc2_pwm_default/group1' defined in btr-shields/boards/seeed/seeeduino_lotus_btr/seeeduino_lotus_btr-pinctrl.dtsi:52 */
				group1 {
					pinmux = < 0x4310 >; /* in btr-shields/boards/seeed/seeeduino_lotus_btr/seeeduino_lotus_btr-pinctrl.dtsi:53 */
				};
			};

			/* node '/soc/pinctrl@41004400/dac_default' defined in btr-shields/boards/seeed/seeeduino_lotus_btr/seeeduino_lotus_btr-pinctrl.dtsi:57 */
			dac_default: dac_default {
				phandle = < 0x9 >; /* in btr-shields/boards/seeed/seeeduino_lotus_btr/seeeduino_lotus_btr.dts:157 */

				/* node '/soc/pinctrl@41004400/dac_default/group1' defined in btr-shields/boards/seeed/seeeduino_lotus_btr/seeeduino_lotus_btr-pinctrl.dtsi:58 */
				group1 {
					pinmux = < 0x1230 >,
					         < 0x1220 >; /* in btr-shields/boards/seeed/seeeduino_lotus_btr/seeeduino_lotus_btr-pinctrl.dtsi:59 */
				};
			};

			/* node '/soc/pinctrl@41004400/adc_default' defined in btr-shields/boards/seeed/seeeduino_lotus_btr/seeeduino_lotus_btr-pinctrl.dtsi:64 */
			adc_default: adc_default {
				phandle = < 0x8 >; /* in btr-shields/boards/seeed/seeeduino_lotus_btr/seeeduino_lotus_btr.dts:164 */

				/* node '/soc/pinctrl@41004400/adc_default/group1' defined in btr-shields/boards/seeed/seeeduino_lotus_btr/seeeduino_lotus_btr-pinctrl.dtsi:65 */
				group1 {
					pinmux = < 0x1230 >,
					         < 0x1281 >,
					         < 0x1291 >,
					         < 0x1240 >,
					         < 0x1250 >,
					         < 0x1221 >; /* in btr-shields/boards/seeed/seeeduino_lotus_btr/seeeduino_lotus_btr-pinctrl.dtsi:66 */
				};
			};

			/* node '/soc/pinctrl@41004400/usb_dc_default' defined in btr-shields/boards/seeed/seeeduino_lotus_btr/seeeduino_lotus_btr-pinctrl.dtsi:75 */
			usb_dc_default: usb_dc_default {
				phandle = < 0xa >; /* in btr-shields/boards/seeed/seeeduino_lotus_btr/seeeduino_lotus_btr.dts:171 */

				/* node '/soc/pinctrl@41004400/usb_dc_default/group1' defined in btr-shields/boards/seeed/seeeduino_lotus_btr/seeeduino_lotus_btr-pinctrl.dtsi:76 */
				group1 {
					pinmux = < 0x6390 >,
					         < 0x6380 >; /* in btr-shields/boards/seeed/seeeduino_lotus_btr/seeeduino_lotus_btr-pinctrl.dtsi:77 */
				};
			};
		};

		/* node '/soc/rtc@40001400' defined in zephyr-rigs/dts/arm/atmel/samd2x.dtsi:194 */
		rtc: rtc@40001400 {
			compatible = "atmel,sam0-rtc";         /* in zephyr-rigs/dts/arm/atmel/samd2x.dtsi:195 */
			reg = < 0x40001400 0x1c >;             /* in zephyr-rigs/dts/arm/atmel/samd2x.dtsi:196 */
			interrupts = < 0x3 0x0 >;              /* in zephyr-rigs/dts/arm/atmel/samd2x.dtsi:197 */
			status = "disabled";                   /* in zephyr-rigs/dts/arm/atmel/samd2x.dtsi:200 */
			alarms-count = < 0x1 >;                /* in zephyr-rigs/dts/arm/atmel/samd2x.dtsi:202 */
			cal-constant = < 0xf4000 >;            /* in zephyr-rigs/dts/arm/atmel/samd2x.dtsi:203 */
			clocks = < &gclk 0x4 >,
			         < &pm 0x18 0x5 >;             /* in zephyr-rigs/dts/arm/atmel/samd21.dtsi:102 */
			clock-names = "GCLK",
			              "PM";                    /* in zephyr-rigs/dts/arm/atmel/samd21.dtsi:103 */
			atmel,assigned-clocks = < &gclk 0x4 >; /* in zephyr-rigs/dts/arm/atmel/samd21.dtsi:104 */
			atmel,assigned-clock-names = "GCLK";   /* in zephyr-rigs/dts/arm/atmel/samd21.dtsi:105 */
		};

		/* node '/soc/adc@42004000' defined in zephyr-rigs/dts/arm/atmel/samd2x.dtsi:206 */
		adc: adc0: adc@42004000 {
			compatible = "atmel,sam0-adc";         /* in zephyr-rigs/dts/arm/atmel/samd2x.dtsi:207 */
			reg = < 0x42004000 0x2b >;             /* in zephyr-rigs/dts/arm/atmel/samd2x.dtsi:208 */
			#io-channel-cells = < 0x1 >;           /* in zephyr-rigs/dts/arm/atmel/samd2x.dtsi:211 */
			prescaler = < 0x4 >;                   /* in zephyr-rigs/dts/arm/atmel/samd2x.dtsi:213 */
			interrupts = < 0x17 0x0 >;             /* in zephyr-rigs/dts/arm/atmel/samd21.dtsi:165 */
			interrupt-names = "resrdy";            /* in zephyr-rigs/dts/arm/atmel/samd21.dtsi:166 */
			clocks = < &gclk 0x1e >,
			         < &pm 0x20 0x10 >;            /* in zephyr-rigs/dts/arm/atmel/samd21.dtsi:167 */
			clock-names = "GCLK",
			              "PM";                    /* in zephyr-rigs/dts/arm/atmel/samd21.dtsi:168 */
			atmel,assigned-clocks = < &gclk 0x3 >; /* in zephyr-rigs/dts/arm/atmel/samd21.dtsi:174 */
			atmel,assigned-clock-names = "GCLK";   /* in zephyr-rigs/dts/arm/atmel/samd21.dtsi:175 */
			pinctrl-0 = < &adc_default >;          /* in btr-shields/boards/seeed/seeeduino_lotus_btr/seeeduino_lotus_btr.dts:164 */
			pinctrl-names = "default";             /* in btr-shields/boards/seeed/seeeduino_lotus_btr/seeeduino_lotus_btr.dts:165 */
			status = "okay";                       /* in ../../../tmp/pytest-of-tobi/pytest-52/test_tier2_accept_zephyr_dts_l0/build/rig/overlay:25 */
			phandle = < 0x11 >;                    /* in btr-shields/boards/seeed/seeeduino_lotus_btr/grove_sockets_btr.dtsi:137 */
		};

		/* node '/soc/dac@42004800' defined in zephyr-rigs/dts/arm/atmel/samd2x.dtsi:216 */
		dac0: dac@42004800 {
			compatible = "atmel,sam0-dac";         /* in zephyr-rigs/dts/arm/atmel/samd2x.dtsi:217 */
			reg = < 0x42004800 0x10 >;             /* in zephyr-rigs/dts/arm/atmel/samd2x.dtsi:218 */
			#io-channel-cells = < 0x0 >;           /* in zephyr-rigs/dts/arm/atmel/samd2x.dtsi:221 */
			interrupts = < 0x19 0x0 >;             /* in zephyr-rigs/dts/arm/atmel/samd21.dtsi:94 */
			clocks = < &gclk 0x21 >,
			         < &pm 0x20 0x12 >;            /* in zephyr-rigs/dts/arm/atmel/samd21.dtsi:95 */
			clock-names = "GCLK",
			              "PM";                    /* in zephyr-rigs/dts/arm/atmel/samd21.dtsi:96 */
			atmel,assigned-clocks = < &gclk 0x0 >; /* in zephyr-rigs/dts/arm/atmel/samd21.dtsi:97 */
			atmel,assigned-clock-names = "GCLK";   /* in zephyr-rigs/dts/arm/atmel/samd21.dtsi:98 */
			status = "okay";                       /* in btr-shields/boards/seeed/seeeduino_lotus_btr/seeeduino_lotus_btr.dts:155 */
			pinctrl-0 = < &dac_default >;          /* in btr-shields/boards/seeed/seeeduino_lotus_btr/seeeduino_lotus_btr.dts:157 */
			pinctrl-names = "default";             /* in btr-shields/boards/seeed/seeeduino_lotus_btr/seeeduino_lotus_btr.dts:158 */
		};

		/* node '/soc/usb@41005000' defined in zephyr-rigs/dts/arm/atmel/samd21.dtsi:20 */
		usb0: zephyr_udc0: usb@41005000 {
			compatible = "atmel,sam0-usb";   /* in zephyr-rigs/dts/arm/atmel/samd21.dtsi:21 */
			reg = < 0x41005000 0x1000 >;     /* in zephyr-rigs/dts/arm/atmel/samd21.dtsi:22 */
			interrupts = < 0x7 0x0 >;        /* in zephyr-rigs/dts/arm/atmel/samd21.dtsi:23 */
			num-bidir-endpoints = < 0x8 >;   /* in zephyr-rigs/dts/arm/atmel/samd21.dtsi:26 */
			status = "okay";                 /* in btr-shields/boards/seeed/seeeduino_lotus_btr/seeeduino_lotus_btr.dts:169 */
			pinctrl-0 = < &usb_dc_default >; /* in btr-shields/boards/seeed/seeeduino_lotus_btr/seeeduino_lotus_btr.dts:171 */
			pinctrl-names = "default";       /* in btr-shields/boards/seeed/seeeduino_lotus_btr/seeeduino_lotus_btr.dts:172 */
		};

		/* node '/soc/dmac@41004800' defined in zephyr-rigs/dts/arm/atmel/samd21.dtsi:29 */
		dmac: dmac@41004800 {
			compatible = "atmel,sam0-dmac"; /* in zephyr-rigs/dts/arm/atmel/samd21.dtsi:30 */
			reg = < 0x41004800 0x50 >;      /* in zephyr-rigs/dts/arm/atmel/samd21.dtsi:31 */
			interrupts = < 0x6 0x0 >;       /* in zephyr-rigs/dts/arm/atmel/samd21.dtsi:32 */
			status = "disabled";            /* in zephyr-rigs/dts/arm/atmel/samd21.dtsi:33 */
			#dma-cells = < 0x2 >;           /* in zephyr-rigs/dts/arm/atmel/samd21.dtsi:35 */
		};

		/* node '/soc/tc@42003800' defined in zephyr-rigs/dts/arm/atmel/samd21.dtsi:38 */
		tc6: tc@42003800 {
			compatible = "atmel,sam0-tc32";        /* in zephyr-rigs/dts/arm/atmel/samd21.dtsi:39 */
			reg = < 0x42003800 0x20 >;             /* in zephyr-rigs/dts/arm/atmel/samd21.dtsi:40 */
			interrupts = < 0x15 0x0 >;             /* in zephyr-rigs/dts/arm/atmel/samd21.dtsi:41 */
			clocks = < &gclk 0x1d >,
			         < &pm 0x20 0xe >;             /* in zephyr-rigs/dts/arm/atmel/samd21.dtsi:42 */
			clock-names = "GCLK",
			              "PM";                    /* in zephyr-rigs/dts/arm/atmel/samd21.dtsi:43 */
			atmel,assigned-clocks = < &gclk 0x0 >; /* in zephyr-rigs/dts/arm/atmel/samd21.dtsi:44 */
			atmel,assigned-clock-names = "GCLK";   /* in zephyr-rigs/dts/arm/atmel/samd21.dtsi:45 */
			status = "disabled";                   /* in zephyr-rigs/dts/arm/atmel/samd21.dtsi:46 */
		};

		/* node '/soc/tcc@42002000' defined in zephyr-rigs/dts/arm/atmel/samd21.dtsi:49 */
		tcc0: tcc@42002000 {
			reg = < 0x42002000 0x80 >;             /* in zephyr-rigs/dts/arm/atmel/samd21.dtsi:51 */
			interrupts = < 0xf 0x0 >;              /* in zephyr-rigs/dts/arm/atmel/samd21.dtsi:52 */
			clocks = < &gclk 0x1a >,
			         < &pm 0x20 0x8 >;             /* in zephyr-rigs/dts/arm/atmel/samd21.dtsi:53 */
			clock-names = "GCLK",
			              "PM";                    /* in zephyr-rigs/dts/arm/atmel/samd21.dtsi:54 */
			atmel,assigned-clocks = < &gclk 0x0 >; /* in zephyr-rigs/dts/arm/atmel/samd21.dtsi:55 */
			atmel,assigned-clock-names = "GCLK";   /* in zephyr-rigs/dts/arm/atmel/samd21.dtsi:56 */
			channels = < 0x4 >;                    /* in zephyr-rigs/dts/arm/atmel/samd21.dtsi:59 */
			counter-size = < 0x18 >;               /* in zephyr-rigs/dts/arm/atmel/samd21.dtsi:60 */
			compatible = "atmel,sam0-tcc-pwm";     /* in btr-shields/boards/seeed/seeeduino_lotus_btr/seeeduino_lotus_btr.dts:125 */
			prescaler = < 0x1 >;                   /* in btr-shields/boards/seeed/seeeduino_lotus_btr/seeeduino_lotus_btr.dts:126 */
			#pwm-cells = < 0x2 >;                  /* in btr-shields/boards/seeed/seeeduino_lotus_btr/seeeduino_lotus_btr.dts:127 */
			pinctrl-0 = < &tcc0_pwm_default >;     /* in btr-shields/boards/seeed/seeeduino_lotus_btr/seeeduino_lotus_btr.dts:129 */
			pinctrl-names = "default";             /* in btr-shields/boards/seeed/seeeduino_lotus_btr/seeeduino_lotus_btr.dts:130 */
			status = "okay";                       /* in ../../../tmp/pytest-of-tobi/pytest-52/test_tier2_accept_zephyr_dts_l0/build/rig/overlay:26 */
			phandle = < 0xf >;                     /* in btr-shields/boards/seeed/seeeduino_lotus_btr/grove_sockets_btr.dtsi:72 */
		};

		/* node '/soc/tcc@42002400' defined in zephyr-rigs/dts/arm/atmel/samd21.dtsi:63 */
		tcc1: tcc@42002400 {
			reg = < 0x42002400 0x80 >;             /* in zephyr-rigs/dts/arm/atmel/samd21.dtsi:65 */
			interrupts = < 0x10 0x0 >;             /* in zephyr-rigs/dts/arm/atmel/samd21.dtsi:66 */
			clocks = < &gclk 0x1a >,
			         < &pm 0x20 0x9 >;             /* in zephyr-rigs/dts/arm/atmel/samd21.dtsi:67 */
			clock-names = "GCLK",
			              "PM";                    /* in zephyr-rigs/dts/arm/atmel/samd21.dtsi:68 */
			atmel,assigned-clocks = < &gclk 0x0 >; /* in zephyr-rigs/dts/arm/atmel/samd21.dtsi:69 */
			atmel,assigned-clock-names = "GCLK";   /* in zephyr-rigs/dts/arm/atmel/samd21.dtsi:70 */
			channels = < 0x2 >;                    /* in zephyr-rigs/dts/arm/atmel/samd21.dtsi:73 */
			counter-size = < 0x18 >;               /* in zephyr-rigs/dts/arm/atmel/samd21.dtsi:74 */
			status = "okay";                       /* in btr-shields/boards/seeed/seeeduino_lotus_btr/seeeduino_lotus_btr.dts:134 */
			compatible = "atmel,sam0-tcc-pwm";     /* in btr-shields/boards/seeed/seeeduino_lotus_btr/seeeduino_lotus_btr.dts:135 */
			prescaler = < 0x1 >;                   /* in btr-shields/boards/seeed/seeeduino_lotus_btr/seeeduino_lotus_btr.dts:136 */
			#pwm-cells = < 0x2 >;                  /* in btr-shields/boards/seeed/seeeduino_lotus_btr/seeeduino_lotus_btr.dts:137 */
			pinctrl-0 = < &tcc1_pwm_default >;     /* in btr-shields/boards/seeed/seeeduino_lotus_btr/seeeduino_lotus_btr.dts:139 */
			pinctrl-names = "default";             /* in btr-shields/boards/seeed/seeeduino_lotus_btr/seeeduino_lotus_btr.dts:140 */
		};

		/* node '/soc/tcc@42002800' defined in zephyr-rigs/dts/arm/atmel/samd21.dtsi:77 */
		tcc2: tcc@42002800 {
			reg = < 0x42002800 0x80 >;             /* in zephyr-rigs/dts/arm/atmel/samd21.dtsi:79 */
			interrupts = < 0x11 0x0 >;             /* in zephyr-rigs/dts/arm/atmel/samd21.dtsi:80 */
			clocks = < &gclk 0x1b >,
			         < &pm 0x20 0xa >;             /* in zephyr-rigs/dts/arm/atmel/samd21.dtsi:81 */
			clock-names = "GCLK",
			              "PM";                    /* in zephyr-rigs/dts/arm/atmel/samd21.dtsi:82 */
			atmel,assigned-clocks = < &gclk 0x0 >; /* in zephyr-rigs/dts/arm/atmel/samd21.dtsi:83 */
			atmel,assigned-clock-names = "GCLK";   /* in zephyr-rigs/dts/arm/atmel/samd21.dtsi:84 */
			channels = < 0x2 >;                    /* in zephyr-rigs/dts/arm/atmel/samd21.dtsi:87 */
			counter-size = < 0x10 >;               /* in zephyr-rigs/dts/arm/atmel/samd21.dtsi:88 */
			status = "okay";                       /* in btr-shields/boards/seeed/seeeduino_lotus_btr/seeeduino_lotus_btr.dts:144 */
			compatible = "atmel,sam0-tcc-pwm";     /* in btr-shields/boards/seeed/seeeduino_lotus_btr/seeeduino_lotus_btr.dts:145 */
			prescaler = < 0x400 >;                 /* in btr-shields/boards/seeed/seeeduino_lotus_btr/seeeduino_lotus_btr.dts:147 */
			#pwm-cells = < 0x2 >;                  /* in btr-shields/boards/seeed/seeeduino_lotus_btr/seeeduino_lotus_btr.dts:148 */
			pinctrl-0 = < &tcc2_pwm_default >;     /* in btr-shields/boards/seeed/seeeduino_lotus_btr/seeeduino_lotus_btr.dts:150 */
			pinctrl-names = "default";             /* in btr-shields/boards/seeed/seeeduino_lotus_btr/seeeduino_lotus_btr.dts:151 */
			phandle = < 0x12 >;                    /* in btr-shields/boards/seeed/seeeduino_lotus_btr/seeeduino_lotus_btr.dts:58 */
		};
	};

	/* node '/cpus' defined in zephyr-rigs/dts/arm/atmel/samd2x.dtsi:40 */
	cpus {
		#address-cells = < 0x1 >; /* in zephyr-rigs/dts/arm/atmel/samd2x.dtsi:41 */
		#size-cells = < 0x0 >;    /* in zephyr-rigs/dts/arm/atmel/samd2x.dtsi:42 */

		/* node '/cpus/cpu@0' defined in zephyr-rigs/dts/arm/atmel/samd2x.dtsi:44 */
		cpu0: cpu@0 {
			compatible = "arm,cortex-m0+";   /* in zephyr-rigs/dts/arm/atmel/samd2x.dtsi:45 */
			reg = < 0x0 >;                   /* in zephyr-rigs/dts/arm/atmel/samd2x.dtsi:46 */
			device_type = "cpu";             /* in zephyr-rigs/dts/arm/atmel/samd2x.dtsi:48 */
			clock-frequency = < 0x2dc6c00 >; /* in btr-shields/boards/seeed/seeeduino_lotus_btr/seeeduino_lotus_btr.dts:72 */
		};
	};

	/* node '/memory@20000000' defined in zephyr-rigs/dts/arm/atmel/samd2x.dtsi:52 */
	sram0: memory@20000000 {
		compatible = "mmio-sram";    /* in zephyr-rigs/dts/arm/atmel/samd2x.dtsi:53 */
		reg = < 0x20000000 0x8000 >; /* in zephyr-rigs/dts/arm/atmel/samx2xx18.dtsi:10 */
	};

	/* node '/device_id@80a00c' defined in zephyr-rigs/dts/arm/atmel/samd2x.dtsi:56 */
	id: device_id@80a00c {
		compatible = "atmel,sam0-id"; /* in zephyr-rigs/dts/arm/atmel/samd2x.dtsi:57 */
		reg = < 0x80a00c 0x4 >,
		      < 0x80a040 0x4 >,
		      < 0x80a044 0x4 >,
		      < 0x80a048 0x4 >;       /* in zephyr-rigs/dts/arm/atmel/samd2x.dtsi:58 */
	};

	/* node '/connector_grove_d2' defined in btr-shields/boards/seeed/seeeduino_lotus_btr/grove_sockets_btr.dtsi:62 */
	grove_d2: connector_grove_d2 {
		compatible = "socket,grove";               /* in btr-shields/boards/seeed/seeeduino_lotus_btr/grove_sockets_btr.dtsi:63 */
		#gpio-cells = < 0x2 >;                     /* in btr-shields/boards/seeed/seeeduino_lotus_btr/grove_sockets_btr.dtsi:64 */
		gpio-map-mask = < 0xffffffff 0xffffffc0 >; /* in btr-shields/boards/seeed/seeeduino_lotus_btr/grove_sockets_btr.dtsi:65 */
		gpio-map-pass-thru = < 0x0 0x3f >;         /* in btr-shields/boards/seeed/seeeduino_lotus_btr/grove_sockets_btr.dtsi:66 */
		gpio-map = < 0x0 0x0 &porta 0xe 0x0 >,
		           < 0x1 0x0 &porta 0x9 0x0 >;     /* in btr-shields/boards/seeed/seeeduino_lotus_btr/grove_sockets_btr.dtsi:67 */
		#pwm-cells = < 0x2 >;                      /* in btr-shields/boards/seeed/seeeduino_lotus_btr/grove_sockets_btr.dtsi:69 */
		pwm-map-mask = < 0xffffffff 0x0 >;         /* in btr-shields/boards/seeed/seeeduino_lotus_btr/grove_sockets_btr.dtsi:70 */
		pwm-map-pass-thru = < 0x0 0xffffffff >;    /* in btr-shields/boards/seeed/seeeduino_lotus_btr/grove_sockets_btr.dtsi:71 */
		pwm-map = < 0x0 0x0 &tcc0 0x0 0x0 >,
		          < 0x1 0x0 &tcc0 0x1 0x0 >;       /* in btr-shields/boards/seeed/seeeduino_lotus_btr/grove_sockets_btr.dtsi:72 */
		phandle = < 0x14 >;                        /* in ../../../tmp/pytest-of-tobi/pytest-52/test_tier2_accept_zephyr_dts_l0/build/rig/overlay:16 */
	};

	/* node '/connector_grove_d3' defined in btr-shields/boards/seeed/seeeduino_lotus_btr/grove_sockets_btr.dtsi:74 */
	grove_d3: connector_grove_d3 {
		compatible = "socket,grove";               /* in btr-shields/boards/seeed/seeeduino_lotus_btr/grove_sockets_btr.dtsi:75 */
		#gpio-cells = < 0x2 >;                     /* in btr-shields/boards/seeed/seeeduino_lotus_btr/grove_sockets_btr.dtsi:76 */
		gpio-map-mask = < 0xffffffff 0xffffffc0 >; /* in btr-shields/boards/seeed/seeeduino_lotus_btr/grove_sockets_btr.dtsi:77 */
		gpio-map-pass-thru = < 0x0 0x3f >;         /* in btr-shields/boards/seeed/seeeduino_lotus_btr/grove_sockets_btr.dtsi:78 */
		gpio-map = < 0x0 0x0 &porta 0x9 0x0 >,
		           < 0x1 0x0 &porta 0x8 0x0 >;     /* in btr-shields/boards/seeed/seeeduino_lotus_btr/grove_sockets_btr.dtsi:79 */
		#pwm-cells = < 0x2 >;                      /* in btr-shields/boards/seeed/seeeduino_lotus_btr/grove_sockets_btr.dtsi:81 */
		pwm-map-mask = < 0xffffffff 0x0 >;         /* in btr-shields/boards/seeed/seeeduino_lotus_btr/grove_sockets_btr.dtsi:82 */
		pwm-map-pass-thru = < 0x0 0xffffffff >;    /* in btr-shields/boards/seeed/seeeduino_lotus_btr/grove_sockets_btr.dtsi:83 */
		pwm-map = < 0x0 0x0 &tcc0 0x1 0x0 >,
		          < 0x1 0x0 &tcc0 0x0 0x0 >;       /* in btr-shields/boards/seeed/seeeduino_lotus_btr/grove_sockets_btr.dtsi:84 */
	};

	/* node '/connector_grove_d4' defined in btr-shields/boards/seeed/seeeduino_lotus_btr/grove_sockets_btr.dtsi:86 */
	grove_d4: connector_grove_d4 {
		compatible = "socket,grove";               /* in btr-shields/boards/seeed/seeeduino_lotus_btr/grove_sockets_btr.dtsi:87 */
		#gpio-cells = < 0x2 >;                     /* in btr-shields/boards/seeed/seeeduino_lotus_btr/grove_sockets_btr.dtsi:88 */
		gpio-map-mask = < 0xffffffff 0xffffffc0 >; /* in btr-shields/boards/seeed/seeeduino_lotus_btr/grove_sockets_btr.dtsi:89 */
		gpio-map-pass-thru = < 0x0 0x3f >;         /* in btr-shields/boards/seeed/seeeduino_lotus_btr/grove_sockets_btr.dtsi:90 */
		gpio-map = < 0x0 0x0 &porta 0x8 0x0 >,
		           < 0x1 0x0 &porta 0xf 0x0 >;     /* in btr-shields/boards/seeed/seeeduino_lotus_btr/grove_sockets_btr.dtsi:91 */
		#pwm-cells = < 0x2 >;                      /* in btr-shields/boards/seeed/seeeduino_lotus_btr/grove_sockets_btr.dtsi:94 */
		pwm-map-mask = < 0xffffffff 0x0 >;         /* in btr-shields/boards/seeed/seeeduino_lotus_btr/grove_sockets_btr.dtsi:95 */
		pwm-map-pass-thru = < 0x0 0xffffffff >;    /* in btr-shields/boards/seeed/seeeduino_lotus_btr/grove_sockets_btr.dtsi:96 */
		pwm-map = < 0x0 0x0 &tcc0 0x0 0x0 >,
		          < 0x1 0x0 &tcc0 0x1 0x0 >;       /* in btr-shields/boards/seeed/seeeduino_lotus_btr/grove_sockets_btr.dtsi:97 */
	};

	/* node '/connector_grove_d5' defined in btr-shields/boards/seeed/seeeduino_lotus_btr/grove_sockets_btr.dtsi:99 */
	grove_d5: connector_grove_d5 {
		compatible = "socket,grove";               /* in btr-shields/boards/seeed/seeeduino_lotus_btr/grove_sockets_btr.dtsi:100 */
		#gpio-cells = < 0x2 >;                     /* in btr-shields/boards/seeed/seeeduino_lotus_btr/grove_sockets_btr.dtsi:101 */
		gpio-map-mask = < 0xffffffff 0xffffffc0 >; /* in btr-shields/boards/seeed/seeeduino_lotus_btr/grove_sockets_btr.dtsi:102 */
		gpio-map-pass-thru = < 0x0 0x3f >;         /* in btr-shields/boards/seeed/seeeduino_lotus_btr/grove_sockets_btr.dtsi:103 */
		gpio-map = < 0x0 0x0 &porta 0xf 0x0 >,
		           < 0x1 0x0 &porta 0x14 0x0 >;    /* in btr-shields/boards/seeed/seeeduino_lotus_btr/grove_sockets_btr.dtsi:104 */
	};

	/* node '/connector_grove_d6' defined in btr-shields/boards/seeed/seeeduino_lotus_btr/grove_sockets_btr.dtsi:106 */
	grove_d6: connector_grove_d6 {
		compatible = "socket,grove";               /* in btr-shields/boards/seeed/seeeduino_lotus_btr/grove_sockets_btr.dtsi:107 */
		#gpio-cells = < 0x2 >;                     /* in btr-shields/boards/seeed/seeeduino_lotus_btr/grove_sockets_btr.dtsi:108 */
		gpio-map-mask = < 0xffffffff 0xffffffc0 >; /* in btr-shields/boards/seeed/seeeduino_lotus_btr/grove_sockets_btr.dtsi:109 */
		gpio-map-pass-thru = < 0x0 0x3f >;         /* in btr-shields/boards/seeed/seeeduino_lotus_btr/grove_sockets_btr.dtsi:110 */
		gpio-map = < 0x0 0x0 &porta 0x14 0x0 >,
		           < 0x1 0x0 &porta 0x15 0x0 >;    /* in btr-shields/boards/seeed/seeeduino_lotus_btr/grove_sockets_btr.dtsi:111 */
	};

	/* node '/connector_grove_d7' defined in btr-shields/boards/seeed/seeeduino_lotus_btr/grove_sockets_btr.dtsi:113 */
	grove_d7: connector_grove_d7 {
		compatible = "socket,grove";               /* in btr-shields/boards/seeed/seeeduino_lotus_btr/grove_sockets_btr.dtsi:114 */
		#gpio-cells = < 0x2 >;                     /* in btr-shields/boards/seeed/seeeduino_lotus_btr/grove_sockets_btr.dtsi:115 */
		gpio-map-mask = < 0xffffffff 0xffffffc0 >; /* in btr-shields/boards/seeed/seeeduino_lotus_btr/grove_sockets_btr.dtsi:116 */
		gpio-map-pass-thru = < 0x0 0x3f >;         /* in btr-shields/boards/seeed/seeeduino_lotus_btr/grove_sockets_btr.dtsi:117 */
		gpio-map = < 0x0 0x0 &porta 0x15 0x0 >,
		           < 0x1 0x0 &porta 0x6 0x0 >;     /* in btr-shields/boards/seeed/seeeduino_lotus_btr/grove_sockets_btr.dtsi:118 */
	};

	/* node '/connector_grove_a0' defined in btr-shields/boards/seeed/seeeduino_lotus_btr/grove_sockets_btr.dtsi:127 */
	grove_a0: connector_grove_a0 {
		compatible = "socket,grove";               /* in btr-shields/boards/seeed/seeeduino_lotus_btr/grove_sockets_btr.dtsi:128 */
		#gpio-cells = < 0x2 >;                     /* in btr-shields/boards/seeed/seeeduino_lotus_btr/grove_sockets_btr.dtsi:129 */
		gpio-map-mask = < 0xffffffff 0xffffffc0 >; /* in btr-shields/boards/seeed/seeeduino_lotus_btr/grove_sockets_btr.dtsi:130 */
		gpio-map-pass-thru = < 0x0 0x3f >;         /* in btr-shields/boards/seeed/seeeduino_lotus_btr/grove_sockets_btr.dtsi:131 */
		gpio-map = < 0x0 0x0 &porta 0x2 0x0 >,
		           < 0x1 0x0 &portb 0x8 0x0 >;     /* in btr-shields/boards/seeed/seeeduino_lotus_btr/grove_sockets_btr.dtsi:132 */
		#io-channel-cells = < 0x1 >;               /* in btr-shields/boards/seeed/seeeduino_lotus_btr/grove_sockets_btr.dtsi:134 */
		io-channel-map-mask = < 0xffffffff >;      /* in btr-shields/boards/seeed/seeeduino_lotus_btr/grove_sockets_btr.dtsi:135 */
		io-channel-map-pass-thru = < 0x0 >;        /* in btr-shields/boards/seeed/seeeduino_lotus_btr/grove_sockets_btr.dtsi:136 */
		io-channel-map = < 0x0 &adc0 0x0 >,
		                 < 0x1 &adc0 0x1 >;        /* in btr-shields/boards/seeed/seeeduino_lotus_btr/grove_sockets_btr.dtsi:137 */
		phandle = < 0x13 >;                        /* in ../../../tmp/pytest-of-tobi/pytest-52/test_tier2_accept_zephyr_dts_l0/build/rig/overlay:9 */
	};

	/* node '/connector_grove_a1' defined in btr-shields/boards/seeed/seeeduino_lotus_btr/grove_sockets_btr.dtsi:139 */
	grove_a1: connector_grove_a1 {
		compatible = "socket,grove";               /* in btr-shields/boards/seeed/seeeduino_lotus_btr/grove_sockets_btr.dtsi:140 */
		#gpio-cells = < 0x2 >;                     /* in btr-shields/boards/seeed/seeeduino_lotus_btr/grove_sockets_btr.dtsi:141 */
		gpio-map-mask = < 0xffffffff 0xffffffc0 >; /* in btr-shields/boards/seeed/seeeduino_lotus_btr/grove_sockets_btr.dtsi:142 */
		gpio-map-pass-thru = < 0x0 0x3f >;         /* in btr-shields/boards/seeed/seeeduino_lotus_btr/grove_sockets_btr.dtsi:143 */
		gpio-map = < 0x0 0x0 &portb 0x8 0x0 >,
		           < 0x1 0x0 &portb 0x9 0x0 >;     /* in btr-shields/boards/seeed/seeeduino_lotus_btr/grove_sockets_btr.dtsi:144 */
		#io-channel-cells = < 0x1 >;               /* in btr-shields/boards/seeed/seeeduino_lotus_btr/grove_sockets_btr.dtsi:146 */
		io-channel-map-mask = < 0xffffffff >;      /* in btr-shields/boards/seeed/seeeduino_lotus_btr/grove_sockets_btr.dtsi:147 */
		io-channel-map-pass-thru = < 0x0 >;        /* in btr-shields/boards/seeed/seeeduino_lotus_btr/grove_sockets_btr.dtsi:148 */
		io-channel-map = < 0x0 &adc0 0x1 >,
		                 < 0x1 &adc0 0x2 >;        /* in btr-shields/boards/seeed/seeeduino_lotus_btr/grove_sockets_btr.dtsi:149 */
	};

	/* node '/connector_grove_a2' defined in btr-shields/boards/seeed/seeeduino_lotus_btr/grove_sockets_btr.dtsi:151 */
	grove_a2: connector_grove_a2 {
		compatible = "socket,grove";               /* in btr-shields/boards/seeed/seeeduino_lotus_btr/grove_sockets_btr.dtsi:152 */
		#gpio-cells = < 0x2 >;                     /* in btr-shields/boards/seeed/seeeduino_lotus_btr/grove_sockets_btr.dtsi:153 */
		gpio-map-mask = < 0xffffffff 0xffffffc0 >; /* in btr-shields/boards/seeed/seeeduino_lotus_btr/grove_sockets_btr.dtsi:154 */
		gpio-map-pass-thru = < 0x0 0x3f >;         /* in btr-shields/boards/seeed/seeeduino_lotus_btr/grove_sockets_btr.dtsi:155 */
		gpio-map = < 0x0 0x0 &portb 0x9 0x0 >,
		           < 0x1 0x0 &porta 0x4 0x0 >;     /* in btr-shields/boards/seeed/seeeduino_lotus_btr/grove_sockets_btr.dtsi:156 */
	};

	/* node '/leds' defined in btr-shields/boards/seeed/seeeduino_lotus_btr/seeeduino_lotus_btr.dts:39 */
	leds {
		compatible = "gpio-leds"; /* in btr-shields/boards/seeed/seeeduino_lotus_btr/seeeduino_lotus_btr.dts:40 */

		/* node '/leds/led_0' defined in btr-shields/boards/seeed/seeeduino_lotus_btr/seeeduino_lotus_btr.dts:41 */
		led: led_0 {
			gpios = < &porta 0x11 0x1 >; /* in btr-shields/boards/seeed/seeeduino_lotus_btr/seeeduino_lotus_btr.dts:42 */
			label = "LED";               /* in btr-shields/boards/seeed/seeeduino_lotus_btr/seeeduino_lotus_btr.dts:43 */
		};

		/* node '/leds/led_1' defined in btr-shields/boards/seeed/seeeduino_lotus_btr/seeeduino_lotus_btr.dts:45 */
		rx_led: led_1 {
			gpios = < &portb 0x3 0x1 >; /* in btr-shields/boards/seeed/seeeduino_lotus_btr/seeeduino_lotus_btr.dts:46 */
			label = "RX_LED";           /* in btr-shields/boards/seeed/seeeduino_lotus_btr/seeeduino_lotus_btr.dts:47 */
		};

		/* node '/leds/led_2' defined in btr-shields/boards/seeed/seeeduino_lotus_btr/seeeduino_lotus_btr.dts:49 */
		tx_led: led_2 {
			gpios = < &porta 0x1b 0x1 >; /* in btr-shields/boards/seeed/seeeduino_lotus_btr/seeeduino_lotus_btr.dts:50 */
			label = "TX_LED";            /* in btr-shields/boards/seeed/seeeduino_lotus_btr/seeeduino_lotus_btr.dts:51 */
		};
	};

	/* node '/pwmleds' defined in btr-shields/boards/seeed/seeeduino_lotus_btr/seeeduino_lotus_btr.dts:55 */
	pwmleds {
		compatible = "pwm-leds"; /* in btr-shields/boards/seeed/seeeduino_lotus_btr/seeeduino_lotus_btr.dts:56 */

		/* node '/pwmleds/pwm_led_0' defined in btr-shields/boards/seeed/seeeduino_lotus_btr/seeeduino_lotus_btr.dts:57 */
		pwm_led: pwm_led_0 {
			pwms = < &tcc2 0x1 0x1312d00 >; /* in btr-shields/boards/seeed/seeeduino_lotus_btr/seeeduino_lotus_btr.dts:58 */
		};
	};

	/* node '/light_1' defined in ../../../tmp/pytest-of-tobi/pytest-52/test_tier2_accept_zephyr_dts_l0/build/rig/overlay:6 */
	light_1 {

		/* node '/light_1/light' defined in ../../../tmp/pytest-of-tobi/pytest-52/test_tier2_accept_zephyr_dts_l0/build/rig/overlay:7 */
		light_1_light: light {
			compatible = "vnd,light-sensor"; /* in ../../../tmp/pytest-of-tobi/pytest-52/test_tier2_accept_zephyr_dts_l0/build/rig/overlay:8 */
			io-channels = < &grove_a0 0x0 >; /* in ../../../tmp/pytest-of-tobi/pytest-52/test_tier2_accept_zephyr_dts_l0/build/rig/overlay:9 */
			status = "okay";                 /* in ../../../tmp/pytest-of-tobi/pytest-52/test_tier2_accept_zephyr_dts_l0/build/rig/overlay:10 */
		};
	};

	/* node '/servo_1' defined in ../../../tmp/pytest-of-tobi/pytest-52/test_tier2_accept_zephyr_dts_l0/build/rig/overlay:13 */
	servo_1 {

		/* node '/servo_1/servo' defined in ../../../tmp/pytest-of-tobi/pytest-52/test_tier2_accept_zephyr_dts_l0/build/rig/overlay:14 */
		servo_1_servo: servo {
			compatible = "vnd,pwm-servo";       /* in ../../../tmp/pytest-of-tobi/pytest-52/test_tier2_accept_zephyr_dts_l0/build/rig/overlay:15 */
			pwms = < &grove_d2 0x0 0x1312d00 >; /* in ../../../tmp/pytest-of-tobi/pytest-52/test_tier2_accept_zephyr_dts_l0/build/rig/overlay:16 */
			status = "okay";                    /* in ../../../tmp/pytest-of-tobi/pytest-52/test_tier2_accept_zephyr_dts_l0/build/rig/overlay:17 */
		};
	};
};
